# STM32H723 register map
File version: 2.2
CPU: CM7 r0p1, little endian, MPU, FPU, 4 interrupt priority bits
Registers are 32-bit, read-write, reset 0x0 unless marked. A register's access mark holds for its fields unless they carry their own. Offsets are from the block's base; [hi:lo] are bit positions.

## ADC3_Common — Analog-to-Digital Converter
Base 0x58026300
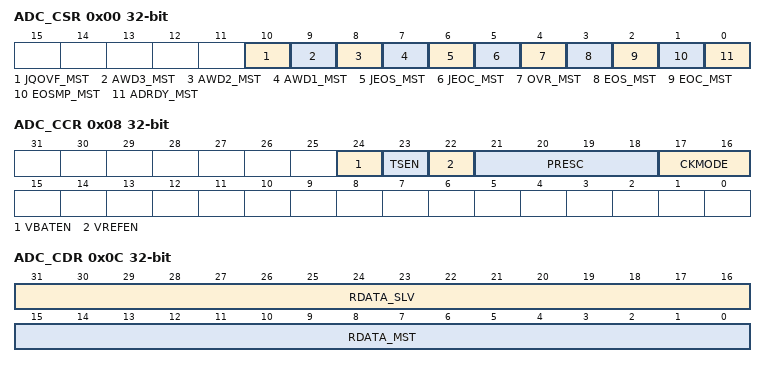
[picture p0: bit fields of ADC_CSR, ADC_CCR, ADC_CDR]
0x00 ADC_CSR ro — ADC common status register
  [10] JQOVF_MST — Injected Context Queue Overflow flag of the master ADC This bit is a copy of the JQOVF bit in the corresponding ADC_ISR register.
  [9] AWD3_MST — Analog watchdog 3 flag of the master ADC This bit is a copy of the AWD3 bit in the corresponding ADC_ISR register.
  [8] AWD2_MST — Analog watchdog 2 flag of the master ADC This bit is a copy of the AWD2 bit in the corresponding ADC_ISR register.
  [7] AWD1_MST — Analog watchdog 1 flag of the master ADC This bit is a copy of the AWD1 bit in the corresponding ADC_ISR register.
  [6] JEOS_MST — End of injected sequence flag of the master ADC This bit is a copy of the JEOS bit in the corresponding ADC_ISR register.
  [5] JEOC_MST — End of injected conversion flag of the master ADC This bit is a copy of the JEOC bit in the corresponding ADC_ISR register.
  [4] OVR_MST — Overrun flag of the master ADC This bit is a copy of the OVR bit in the corresponding ADC_ISR register.
  [3] EOS_MST — End of regular sequence flag of the master ADC This bit is a copy of the EOS bit in the corresponding ADC_ISR register.
  [2] EOC_MST — End of regular conversion of the master ADC This bit is a copy of the EOC bit in the corresponding ADC_ISR register.
  [1] EOSMP_MST — End of Sampling phase flag of the master ADC This bit is a copy of the EOSMP bit in the corresponding ADC_ISR register.
  [0] ADRDY_MST — Master ADC ready This bit is a copy of the ADRDY bit in the corresponding ADC_ISR register.
0x08 ADC_CCR — ADC common control register
  [24] VBATEN — VBAT enable This bit is set and cleared by software to control.
    0=VBAT channel disabled; 1=VBAT channel enabled
  [23] TSEN — VSENSE enable This bit is set and cleared by software to control VSENSE.
    0=Temperature sensor channel disabled; 1=Temperature sensor channel enabled
  [22] VREFEN — VREFINT enable This bit is set and cleared by software to enable/disable the VREFINT channel.
    0=VREFINT channel disabled; 1=VREFINT channel enabled
  [21:18] PRESC — ADC prescaler These bits are set and cleared by software to select the frequency of the clock to the ADC. The clock is common for all the ADCs. other: reserved Note: The software is allowed to write these bits only when the ADC is disabled (ADCAL = 0, JADSTART = 0, ADSTART = 0, ADSTP = 0, ADDIS = 0 and ADEN = 0). The ADC prescaler value is applied only when CKMODE[1:0] = 0b00.
    0=input ADC clock not divided; 1=input ADC clock divided by 2; 2=input ADC clock divided by 4; 3=input ADC clock divided by 6; 4=input ADC clock divided by 8; 5=input ADC clock divided by 10; 6=input ADC clock divided by 12; 7=input ADC clock divided by 16; 8=input ADC clock divided by 32; 9=input ADC clock divided by 64; 10=input ADC clock divided by 128; 11=input ADC clock divided by 256
  [17:16] CKMODE — ADC clock mode These bits are set and cleared by software to define the ADC clock scheme (which is common to both master and slave ADCs): In all synchronous clock modes, there is no jitter in the delay from a timer trigger to the start of a conversion. Note: The software is allowed to write these bits only when the ADCs are disabled (ADCAL = 0, JADSTART = 0, ADSTART = 0, ADSTP = 0, ADDIS = 0 and ADEN = 0).
    0=adc_ker_ck (x = 3) (Asynchronous clock mode), generated at product level (refer to Section 6: Reset and clock control (RCC)); 1=adc_hclk/1 (Synchronous clock mode). This configuration must be enabled only if the AHB clock prescaler is set to 1 (HPRE[3:0] = 0XXX in RCC_CFGR register) and if the system clock has a 50% duty cycle.; 2=adc_hclk/2 (Synchronous clock mode); 3=adc_hclk/4 (Synchronous clock mode)
0x0C ADC_CDR ro — ADC common regular data register for dual and triple modes
  [31:16] RDATA_SLV — Regular data of the slave ADC
  [15:0] RDATA_MST — Regular data of the master ADC
0x10 ADC_CDR2 ro — ADC x common regular data register for 32-bit dual mode
  [31:0] RDATA_ALT — Regular data of the master/slave alternated ADCs
